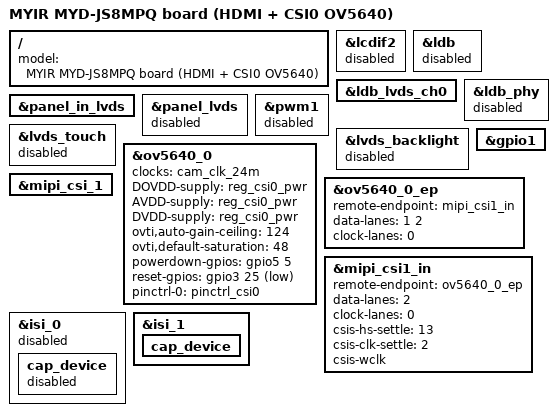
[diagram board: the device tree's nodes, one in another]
// SPDX-License-Identifier: (GPL-2.0+ OR MIT)
/*
 * MYD-JS8MPQ native HDMI + CSI0 OV5640 variant.
 *
 * The validated OV5640 pipeline is inherited unchanged from myd-js8mpq.dts:
 * ov5640_0 (i2c3) -> mipi_csi_1 -> isi_1 -> /dev/video*.
 */

#include "myd-js8mpq.dts"

/ {
	model = "MYIR MYD-JS8MPQ board (HDMI + CSI0 OV5640)";
};

/*
 * This variant has one display output: the native HDMI path inherited from
 * myd-js8mpq.dts.  Turn off the base DTS LVDS0 path and its panel controls.
 */
&lcdif2 {
	status = "disabled";
};

&ldb {
	status = "disabled";
};

&ldb_lvds_ch0 {
	/delete-property/ remote-endpoint;
};

&panel_in_lvds {
	/delete-property/ remote-endpoint;
};

&panel_lvds {
	status = "disabled";
};

&ldb_phy {
	status = "disabled";
};

&pwm1 {
	status = "disabled";
};

&lvds_backlight {
	status = "disabled";
};

&lvds_touch {
	status = "disabled";
};

&gpio1 {
	/delete-node/ lvds0-sel-hog;
};

/*
 * Keep the EVK OV5640 topology, but use the MYD-JS8MPQ camera connector's
 * actual power, reset and fixed 24 MHz clock resources.
 */
&ov5640_0 {
	clocks = <&cam_clk_24m>;
	clock-names = "xclk";
	DOVDD-supply = <&reg_csi0_pwr>;
	AVDD-supply = <&reg_csi0_pwr>;
	DVDD-supply = <&reg_csi0_pwr>;
	/* Board-tuned limits: 7.75x AGC ceiling and reduced chroma noise. */
	ovti,auto-gain-ceiling = <124>;
	ovti,default-saturation = <48>;
	powerdown-gpios = <&gpio5 5 GPIO_ACTIVE_HIGH>;
	reset-gpios = <&gpio3 25 GPIO_ACTIVE_LOW>;
	pinctrl-names = "default";
	pinctrl-0 = <&pinctrl_csi0>;
	status = "okay";
};

&ov5640_0_ep {
	remote-endpoint = <&mipi_csi1_in>;
	data-lanes = <1 2>;
	clock-lanes = <0>;
};

&mipi_csi_1 {
	status = "okay";
};

/* Match the validated i.MX8MP EVK receiver timing for OV5640. */
&mipi_csi1_in {
	remote-endpoint = <&ov5640_0_ep>;
	data-lanes = <2>;
	clock-lanes = <0>;
	csis-hs-settle = <13>;
	csis-clk-settle = <2>;
	csis-wclk;
};

&isi_0 {
	status = "disabled";

	cap_device {
		status = "disabled";
	};
};

&isi_1 {
	status = "okay";

	cap_device {
		status = "okay";
	};
};
